# f2838x_mem_cfg_regs register map
Vendor: Texas Instruments
Peripheral module from a debugger description file (folder C2000).
Address unit: 16 bits
Registers are 32-bit, read-write, no defined reset value unless marked. A register's access mark holds for its fields unless they carry their own. Offsets are as the file gives them; lines under a group give offsets from that group; [hi:lo] are bit positions; {n}, {i} and the like mark numbered series; 'fields as' and 'values as' point back to an identical list; <NAME> marks a mode.

## MEM_CFG_REGS — MEM CFG Registers
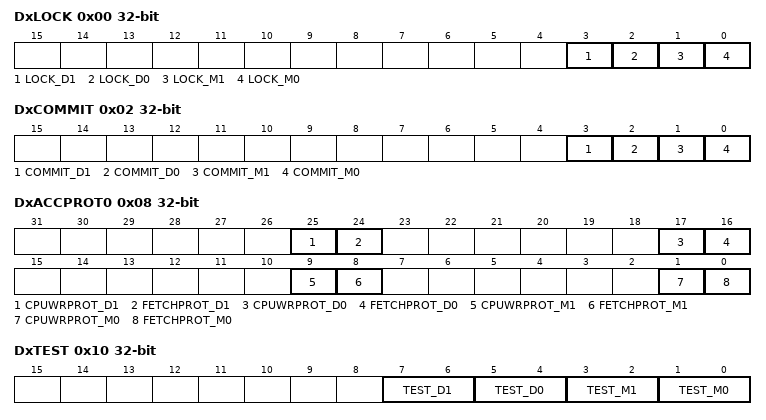
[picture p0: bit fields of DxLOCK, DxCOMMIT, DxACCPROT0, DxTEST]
0x00 DxLOCK — Dedicated RAM Config Lock Register
  [3] LOCK_D1 — D1 RAM Lock bits
  [2] LOCK_D0 — D0 RAM Lock bits
  [1] LOCK_M1 — M1 RAM Lock bits
  [0] LOCK_M0 — M0 RAM Lock bits
0x02 DxCOMMIT — Dedicated RAM Config Lock Commit Register
  [3] COMMIT_D1 — D1 RAM Permanent Lock bits
  [2] COMMIT_D0 — D0 RAM Permanent Lock bits
  [1] COMMIT_M1 — M1 RAM Permanent Lock bits
  [0] COMMIT_M0 — M0 RAM Permanent Lock bits
0x08 DxACCPROT0 — Dedicated RAM Config Register
  [25] CPUWRPROT_D1 — CPU WR Protection For D1 RAM
  [24] FETCHPROT_D1 — Fetch Protection For D1 RAM
  [17] CPUWRPROT_D0 — CPU WR Protection For D0 RAM
  [16] FETCHPROT_D0 — Fetch Protection For D0 RAM
  [9] CPUWRPROT_M1 — CPU WR Protection For M1 RAM
  [8] FETCHPROT_M1 — Fetch Protection For M1 RAM
  [1] CPUWRPROT_M0 — CPU WR Protection For M0 RAM
  [0] FETCHPROT_M0 — Fetch Protection For M0 RAM
0x10 DxTEST — Dedicated RAM TEST Register
  [7:6] TEST_D1 — Selects the different modes for D1 RAM
  [5:4] TEST_D0 — Selects the different modes for D0 RAM
  [3:2] TEST_M1 — Selects the different modes for M1 RAM
  [1:0] TEST_M0 — Selects the different modes for M0 RAM
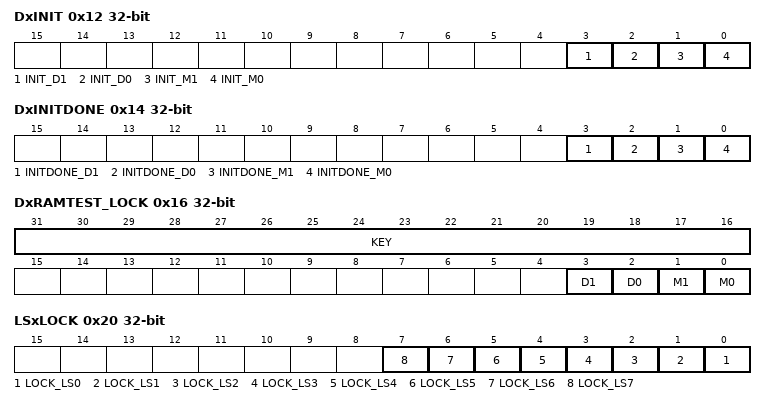
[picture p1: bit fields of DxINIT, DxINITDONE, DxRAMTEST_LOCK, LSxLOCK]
0x12 DxINIT — Dedicated RAM Init Register
  [3] INIT_D1 — RAM Initialization control for D1 RAM.
  [2] INIT_D0 — RAM Initialization control for D0 RAM.
  [1] INIT_M1 — RAM Initialization control for M1 RAM.
  [0] INIT_M0 — RAM Initialization control for M0 RAM.
0x14 DxINITDONE ro — Dedicated RAM InitDone Status Register
  [3] INITDONE_D1 — RAM Initialization status for D1 RAM.
  [2] INITDONE_D0 — RAM Initialization status for D0 RAM.
  [1] INITDONE_M1 — RAM Initialization status for M1 RAM.
  [0] INITDONE_M0 — RAM Initialization status for M0 RAM.
0x16 DxRAMTEST_LOCK — Lock register to Dx RAM TEST registers
  [31:16] KEY
  [3] D1 — DxTEST.TEST_D1 LOCK
  [2] D0 — DxTEST.TEST_D0 LOCK
  [1] M1 — DxTEST.TEST_M1 LOCK
  [0] M0 — DxTEST.TEST_M0 LOCK
0x20 LSxLOCK — Local Shared RAM Config Lock Register
  [n] LOCK_LS{n} (n=0..7) — LS{n} RAM Lock bits
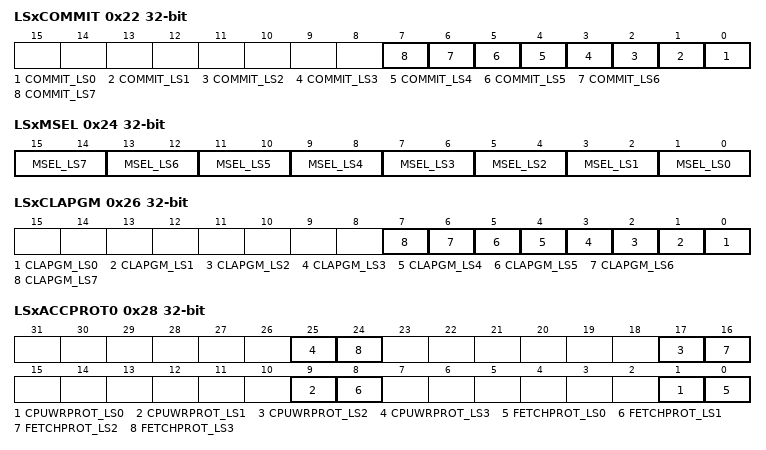
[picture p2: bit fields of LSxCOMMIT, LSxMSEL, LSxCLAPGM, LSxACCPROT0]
0x22 LSxCOMMIT — Local Shared RAM Config Lock Commit Register
  [n] COMMIT_LS{n} (n=0..7) — LS{n} RAM Permanent Lock bits
0x24 LSxMSEL — Local Shared RAM Master Sel Register
  [2n+1:2n] MSEL_LS{n} (n=0..7) — Master Select for LS{n} RAM
0x26 LSxCLAPGM — Local Shared RAM Prog/Exe control Register
  [n] CLAPGM_LS{n} (n=0..7) — Selects LS{n} RAM as program vs data memory for CLA
0x28 LSxACCPROT0 — Local Shared RAM Config Register 0
  [8n+1] CPUWRPROT_LS{n} (n=0..3) — CPU WR Protection For LS{n} RAM
  [8n] FETCHPROT_LS{n} (n=0..3) — Fetch Protection For LS{n} RAM
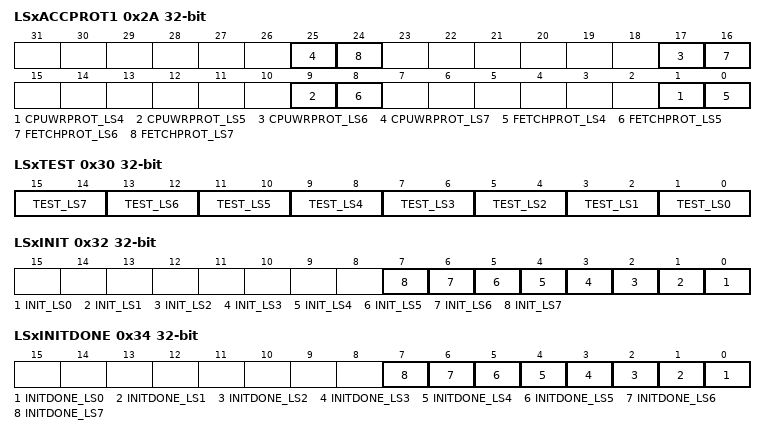
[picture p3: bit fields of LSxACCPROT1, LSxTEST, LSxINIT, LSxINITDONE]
0x2A LSxACCPROT1 — Local Shared RAM Config Register 1
  [8n-31] CPUWRPROT_LS{n} (n=4..7) — CPU WR Protection For LS{n} RAM
  [8n-32] FETCHPROT_LS{n} (n=4..7) — Fetch Protection For LS{n} RAM
0x30 LSxTEST — Local Shared RAM TEST Register
  [2n+1:2n] TEST_LS{n} (n=0..7) — Selects the different modes for LS{n} RAM
0x32 LSxINIT — Local Shared RAM Init Register
  [n] INIT_LS{n} (n=0..7) — RAM Initialization control for LS{n} RAM.
0x34 LSxINITDONE ro — Local Shared RAM InitDone Status Register
  [n] INITDONE_LS{n} (n=0..7) — RAM Initialization status for LS{n} RAM.
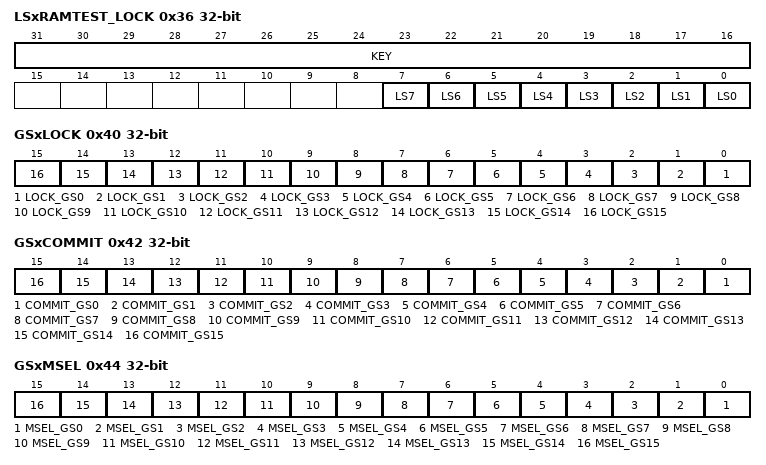
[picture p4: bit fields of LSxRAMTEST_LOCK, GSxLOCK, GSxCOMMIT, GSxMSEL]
0x36 LSxRAMTEST_LOCK — Lock register to LSx RAM TEST registers
  [31:16] KEY
  [n] LS{n} (n=0..7) — LSxTEST.TEST_LS{n} LOCK
0x40 GSxLOCK — Global Shared RAM Config Lock Register
  [n] LOCK_GS{n} (n=0..15) — GS{n} RAM Lock bits
0x42 GSxCOMMIT — Global Shared RAM Config Lock Commit Register
  [n] COMMIT_GS{n} (n=0..15) — GS{n} RAM Permanent Lock bits
0x44 GSxMSEL — Global Shared RAM Master Sel Register
  [n] MSEL_GS{n} (n=0..15) — Master Select for GS{n} RAM
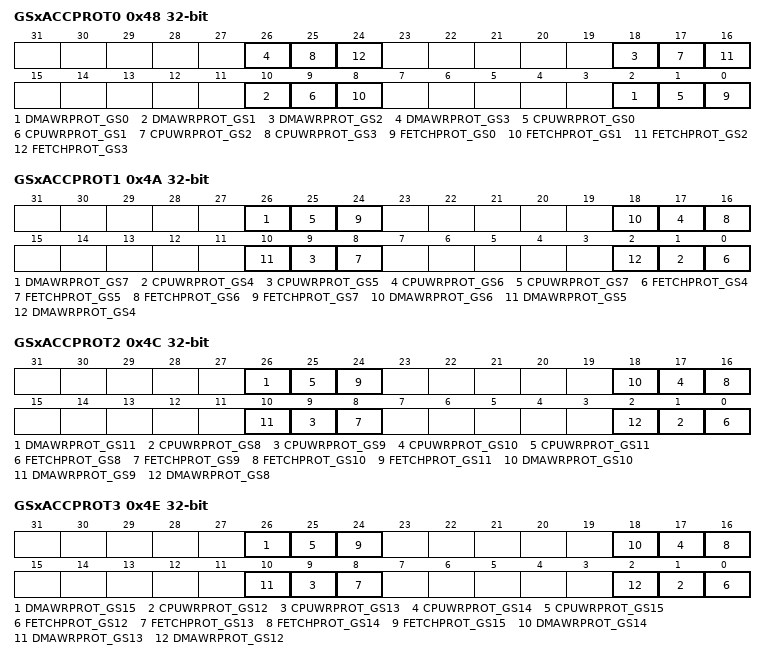
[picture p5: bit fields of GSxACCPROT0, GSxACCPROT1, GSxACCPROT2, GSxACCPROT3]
0x48 GSxACCPROT0 — Global Shared RAM Access Protection Register 0
  [8n+2] DMAWRPROT_GS{n} (n=0..3) — DMA WR Protection For GS{n} RAM
  [8n+1] CPUWRPROT_GS{n} (n=0..3) — CPU WR Protection For GS{n} RAM
  [8n] FETCHPROT_GS{n} (n=0..3) — Fetch Protection For GS{n} RAM
0x4A GSxACCPROT1 — Global Shared RAM Access Protection Register 1
  [26] DMAWRPROT_GS7 — DMA WR Protection For GS7RAM
  [8n-31] CPUWRPROT_GS{n} (n=4..7) — CPU WR Protection For GS{n} RAM
  [8n-32] FETCHPROT_GS{n} (n=4..7) — Fetch Protection For GS{n} RAM
  [18] DMAWRPROT_GS6 — DMA WR Protection For GS6RAM
  [10] DMAWRPROT_GS5 — DMA WR Protection For GS5RAM
  [2] DMAWRPROT_GS4 — DMA WR Protection For GS4 RAM
0x4C GSxACCPROT2 — Global Shared RAM Access Protection Register 2
  [26] DMAWRPROT_GS11 — DMA WR Protection For GS11RAM
  [8n-63] CPUWRPROT_GS{n} (n=8..11) — CPU WR Protection For GS{n} RAM
  [8n-64] FETCHPROT_GS{n} (n=8..11) — Fetch Protection For GS{n} RAM
  [18] DMAWRPROT_GS10 — DMA WR Protection For GS10RAM
  [10] DMAWRPROT_GS9 — DMA WR Protection For GS9RAM
  [2] DMAWRPROT_GS8 — DMA WR Protection For GS8 RAM
0x4E GSxACCPROT3 — Global Shared RAM Access Protection Register 3
  [26] DMAWRPROT_GS15 — DMA WR Protection For GS15RAM
  [8n-95] CPUWRPROT_GS{n} (n=12..15) — CPU WR Protection For GS{n} RAM
  [8n-96] FETCHPROT_GS{n} (n=12..15) — Fetch Protection For GS{n} RAM
  [18] DMAWRPROT_GS14 — DMA WR Protection For GS14RAM
  [10] DMAWRPROT_GS13 — DMA WR Protection For GS13RAM
  [2] DMAWRPROT_GS12 — DMA WR Protection For GS12 RAM
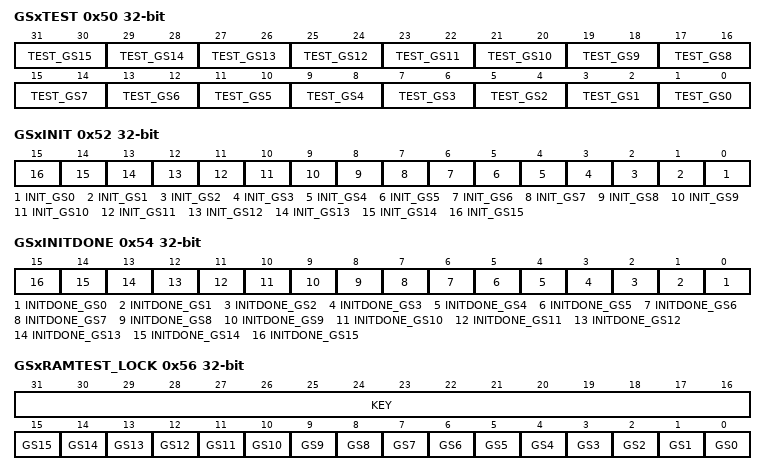
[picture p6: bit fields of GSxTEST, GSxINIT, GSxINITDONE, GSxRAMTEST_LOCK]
0x50 GSxTEST — Global Shared RAM TEST Register
  [2n+1:2n] TEST_GS{n} (n=0..15) — Selects the different modes for GS{n} RAM
0x52 GSxINIT — Global Shared RAM Init Register
  [n] INIT_GS{n} (n=0..15) — RAM Initialization control for GS{n} RAM.
0x54 GSxINITDONE ro — Global Shared RAM InitDone Status Register
  [n] INITDONE_GS{n} (n=0..15) — RAM Initialization status for GS{n} RAM.
0x56 GSxRAMTEST_LOCK — Lock register to GSx RAM TEST registers
  [31:16] KEY
  [n] GS{n} (n=0..15) — GSxTEST.TEST_GS{n} LOCK
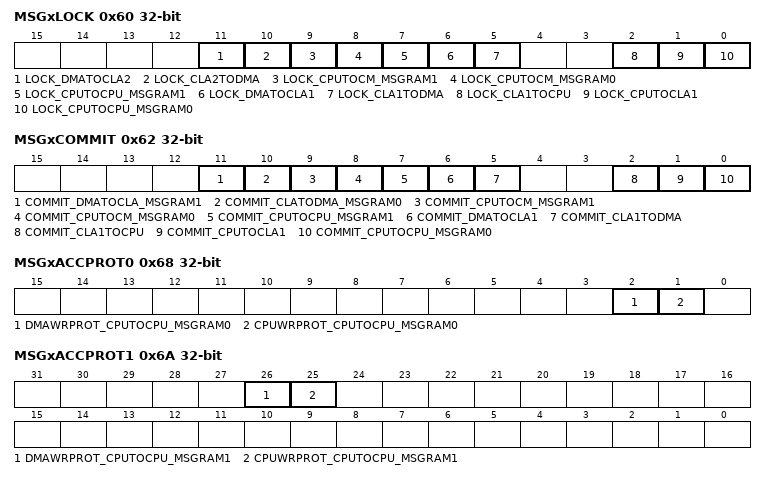
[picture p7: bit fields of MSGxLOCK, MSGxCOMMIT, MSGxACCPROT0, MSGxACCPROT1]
0x60 MSGxLOCK — Message RAM Config Lock Register
  [11] LOCK_DMATOCLA2 — Lock bit of DMA to CLA MSG RAM control fields
  [10] LOCK_CLA2TODMA — Lock bit of CLA to DMA MSG RAM control fields
  [9] LOCK_CPUTOCM_MSGRAM1 — Lock bit of CPU to CM MSG RAM1 control fields
  [8] LOCK_CPUTOCM_MSGRAM0 — Lock bit of CPU to CM MSG RAM0 control fields
  [7] LOCK_CPUTOCPU_MSGRAM1 — Lock bit of CPU to CPU MSG RAM1 control fields
  [6] LOCK_DMATOCLA1 — DMATOCLA1 RAM control fields lock bit
  [5] LOCK_CLA1TODMA — CLA1TODMA RAM control fields lock bit
  [2] LOCK_CLA1TOCPU — CLA1TOCPU RAM Lock bits
  [1] LOCK_CPUTOCLA1 — CPUTOCLA1 RAM Lock bits
  [0] LOCK_CPUTOCPU_MSGRAM0 — CPUTOCPU RAM Lock bits
0x62 MSGxCOMMIT — Message RAM Config Lock Commit Register
  [11] COMMIT_DMATOCLA_MSGRAM1 — Commint bit of DMA to CLA MSG RAM control fields
  [10] COMMIT_CLATODMA_MSGRAM0 — Commint bit of CLA to DMA MSG RAM control fields
  [9] COMMIT_CPUTOCM_MSGRAM1 — Commint bit of CPU to CM MSG RAM1 control fields
  [8] COMMIT_CPUTOCM_MSGRAM0 — Commint bit of CPU to CM MSG RAM0 control fields
  [7] COMMIT_CPUTOCPU_MSGRAM1 — Commint bit of CPU to CPU MSG RAM1 control fields
  [6] COMMIT_DMATOCLA1 — DMATOCLA1 RAM control fields COMMIT bit
  [5] COMMIT_CLA1TODMA — CLA1TODMA RAM control fields COMMIT bit
  [2] COMMIT_CLA1TOCPU — CLA1TOCPU RAM control fields COMMIT bit
  [1] COMMIT_CPUTOCLA1 — CPUTOCLA1 RAM control fields COMMIT bit
  [0] COMMIT_CPUTOCPU_MSGRAM0 — CPUTOCPU RAM control fields COMMIT bit
0x68 MSGxACCPROT0 — Message RAM Access Protection Register 0
  [2] DMAWRPROT_CPUTOCPU_MSGRAM0 — DMA WR Protection For CPUTOCPU_MSGRAM0 RAM
  [1] CPUWRPROT_CPUTOCPU_MSGRAM0 — CPU WR Protection For CPUTOCPU_MSGRAM0 RAM
0x6A MSGxACCPROT1 — Message RAM Access Protection Register 1
  [26] DMAWRPROT_CPUTOCPU_MSGRAM1 — DMA WR Protection For CPUTOCPU_MSGRAM1RAM
  [25] CPUWRPROT_CPUTOCPU_MSGRAM1 — CPU WR Protection For CPUTOCPU_MSGRAM1 RAM
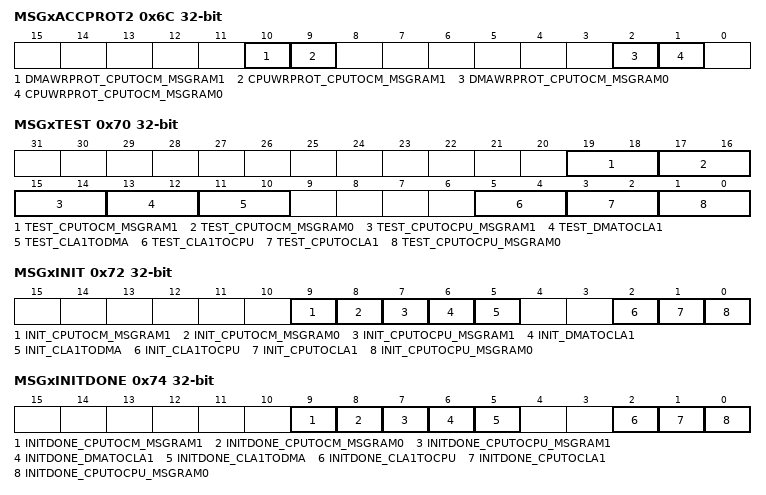
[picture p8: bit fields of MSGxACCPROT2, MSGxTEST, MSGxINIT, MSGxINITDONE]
0x6C MSGxACCPROT2 — Message RAM Access Protection Register 2
  [10] DMAWRPROT_CPUTOCM_MSGRAM1 — DMA WR Protection For CPUTOCM_MSGRAM1RAM
  [9] CPUWRPROT_CPUTOCM_MSGRAM1 — CPU WR Protection For CPUTOCM_MSGRAM1 RAM
  [2] DMAWRPROT_CPUTOCM_MSGRAM0 — DMA WR Protection For CPUTOCM_MSGRAM0 RAM
  [1] CPUWRPROT_CPUTOCM_MSGRAM0 — CPU WR Protection For CPUTOCM_MSGRAM0 RAM
0x70 MSGxTEST — Message RAM TEST Register
  [19:18] TEST_CPUTOCM_MSGRAM1 — CPU to CM Mode Select
  [17:16] TEST_CPUTOCM_MSGRAM0 — CPU to CM Mode Select
  [15:14] TEST_CPUTOCPU_MSGRAM1 — CPU to CPU Mode Select
  [13:12] TEST_DMATOCLA1 — DMA to CLA1 MSG RAM Mode Select
  [11:10] TEST_CLA1TODMA — CLA1 to DMA MSG RAM Mode Select
  [5:4] TEST_CLA1TOCPU — CLA1 to CPU MSG RAM Mode Select
  [3:2] TEST_CPUTOCLA1 — CPU to CLA1 MSG RAM Mode Select
  [1:0] TEST_CPUTOCPU_MSGRAM0 — CPU to CPU Mode Select
0x72 MSGxINIT — Message RAM Init Register
  [9] INIT_CPUTOCM_MSGRAM1 — Initialization control for CPU to CM MSG RAM1
  [8] INIT_CPUTOCM_MSGRAM0 — Initialization control for CPU to CM MSG RAM0
  [7] INIT_CPUTOCPU_MSGRAM1 — Initialization control for CPU to CPU MSG RAM1
  [6] INIT_DMATOCLA1 — Initialization control for DMA to CLA1 MSG RAM
  [5] INIT_CLA1TODMA — Initialization control for CLA1 to DMA MSG RAM
  [2] INIT_CLA1TOCPU — Initialization control for CLA1TOCPU MSG RAM
  [1] INIT_CPUTOCLA1 — Initialization control for CPUTOCLA1 MSG RAM
  [0] INIT_CPUTOCPU_MSGRAM0 — Initialization control for CPU to CPU MSG RAM0
0x74 MSGxINITDONE ro — Message RAM InitDone Status Register
  [9] INITDONE_CPUTOCM_MSGRAM1 — Initialization status for CPU to CM MSG RAM1
  [8] INITDONE_CPUTOCM_MSGRAM0 — Initialization status for CPU to CM MSG RAM0
  [7] INITDONE_CPUTOCPU_MSGRAM1 — Initialization status for CPU to CPU MSG RAM1
  [6] INITDONE_DMATOCLA1 — Initialization status for DMA to CLA1 MSG RAM
  [5] INITDONE_CLA1TODMA — Initialization status for CLA1 to DMA MSG RAM
  [2] INITDONE_CLA1TOCPU — Initialization status for CLA1 to CPU MSG RAM
  [1] INITDONE_CPUTOCLA1 — Initialization status for CPU to CLA1 MSG RAM
  [0] INITDONE_CPUTOCPU_MSGRAM0 — Initialization status for CPU to CPU MSG RAM
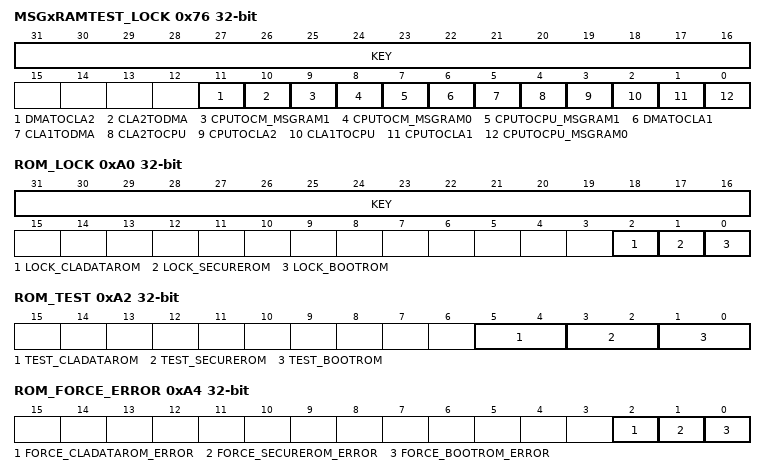
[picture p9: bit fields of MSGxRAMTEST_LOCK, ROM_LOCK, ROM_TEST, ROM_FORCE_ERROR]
0x76 MSGxRAMTEST_LOCK — Lock register to MSGx RAM TEST registers
  [31:16] KEY
  [11] DMATOCLA2 — MSGxTEST.TEST_DMATOCLA2 LOCK
  [10] CLA2TODMA — MSGxTEST.TEST_CLA2TODMA LOCK
  [9] CPUTOCM_MSGRAM1 — MSGxTEST.TEST_CPUTOCM_MSGRAM1 LOCK
  [8] CPUTOCM_MSGRAM0 — MSGxTEST.TEST_CPUTOCM_MSGRAM0 LOCK
  [7] CPUTOCPU_MSGRAM1 — MSGxTEST.TEST_CPUTOCPU_MSGRAM1 LOCK
  [6] DMATOCLA1 — MSGxTEST.TEST_DMATOCLA1 LOCK
  [5] CLA1TODMA — MSGxTEST.TEST_CLA1TODMA LOCK
  [4] CLA2TOCPU — MSGxTEST.TEST_CLA2TOCPU LOCK
  [3] CPUTOCLA2 — MSGxTEST.TEST_CPUTOCLA2 LOCK
  [2] CLA1TOCPU — MSGxTEST.TEST_CLA1TOCPU LOCK
  [1] CPUTOCLA1 — MSGxTEST.TEST_CPUTOCLA1 LOCK
  [0] CPUTOCPU_MSGRAM0 — MSGxTEST.TEST_CPUTOCPU_MSGRAM0 LOCK
0xA0 ROM_LOCK — ROM Config Lock Register
  [31:16] KEY
  [2] LOCK_CLADATAROM — CLADATAROM Lock bits
  [1] LOCK_SECUREROM — SECUREROM Lock bits
  [0] LOCK_BOOTROM — BOOTROM Lock bits
0xA2 ROM_TEST
  [5:4] TEST_CLADATAROM — Selects the different modes for CLADATAROM
  [3:2] TEST_SECUREROM — Selects the different modes for SECUREROM
  [1:0] TEST_BOOTROM — Selects the different modes for BOOTROM
0xA4 ROM_FORCE_ERROR
  [2] FORCE_CLADATAROM_ERROR — Force CLADATAROM Parity Error
  [1] FORCE_SECUREROM_ERROR — Force SECUREROM Parity Error
  [0] FORCE_BOOTROM_ERROR — Force Bootrom Parity Error
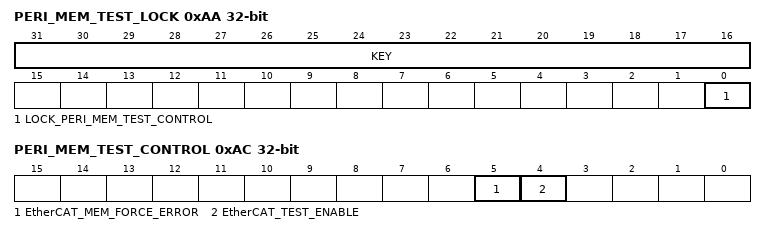
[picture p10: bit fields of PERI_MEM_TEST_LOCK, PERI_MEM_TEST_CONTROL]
0xAA PERI_MEM_TEST_LOCK — Peripheral Memory Test Lock Register
  [31:16] KEY
  [0] LOCK_PERI_MEM_TEST_CONTROL — PERI_MEM_TEST_CONTROL Lock bit
0xAC PERI_MEM_TEST_CONTROL — Peripheral Memory Test control Register
  [5] EtherCAT_MEM_FORCE_ERROR — Force Parity Error on EtherCAT RAM
  [4] EtherCAT_TEST_ENABLE — EtherCAT Test mode enable
